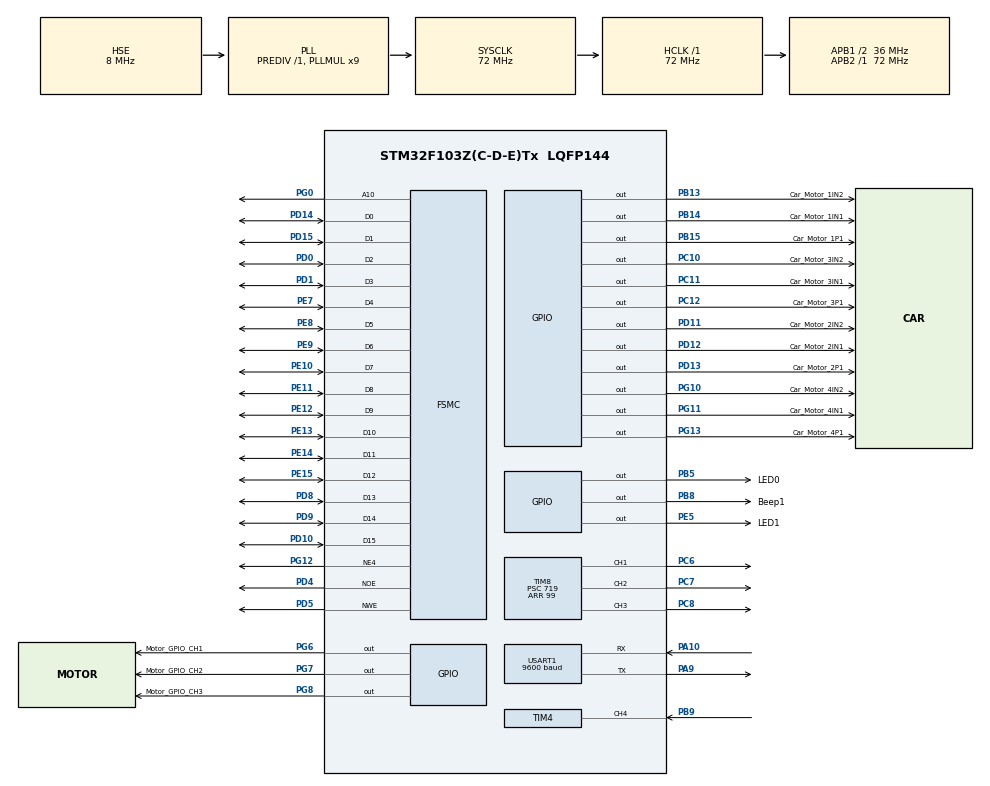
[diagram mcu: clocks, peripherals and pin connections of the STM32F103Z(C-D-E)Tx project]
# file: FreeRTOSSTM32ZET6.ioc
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Dma.Request0=USART1_RX
Dma.Request1=USART1_TX
Dma.USART1_RX.0.Direction=DMA_PERIPH_TO_MEMORY
Dma.USART1_RX.0.Instance=DMA1_Channel5
Dma.USART1_RX.0.MemDataAlignment=DMA_MDATAALIGN_BYTE
Dma.USART1_RX.0.MemInc=DMA_MINC_ENABLE
Dma.USART1_RX.0.Mode=DMA_CIRCULAR
Dma.USART1_RX.0.PeriphDataAlignment=DMA_PDATAALIGN_BYTE
Dma.USART1_RX.0.PeriphInc=DMA_PINC_DISABLE
Dma.USART1_RX.0.Priority=DMA_PRIORITY_LOW
Dma.USART1_TX.1.Direction=DMA_MEMORY_TO_PERIPH
Dma.USART1_TX.1.Instance=DMA1_Channel4
Dma.USART1_TX.1.MemDataAlignment=DMA_MDATAALIGN_BYTE
Dma.USART1_TX.1.MemInc=DMA_MINC_ENABLE
Dma.USART1_TX.1.Mode=DMA_NORMAL
Dma.USART1_TX.1.PeriphDataAlignment=DMA_PDATAALIGN_BYTE
Dma.USART1_TX.1.PeriphInc=DMA_PINC_DISABLE
Dma.USART1_TX.1.Priority=DMA_PRIORITY_LOW
FREERTOS.BinarySemaphores01=uart1_printf_gsem,Dynamic,NULL,Available;uart1_rxok_gsem,Dynamic,NULL,Available;LCD_refresh_gsem,Dynamic,NULL,Available;uart1_data_handle_gsem,Dynamic,NULL,Available
FREERTOS.Tasks01=defauleTask,24,128,StartdefauleTask,As weak,NULL,Dynamic,NULL,NULL;UART1_recv_Task,16,128,StartUART1_recv_TaskFunction,As external,&sys_use_data,Dynamic,NULL,NULL;LCDDisplayTask,8,128,StartLCDDisplayTaskFunction,As external,&sys_use_data,Dynamic,NULL,NULL;LEDProcessedTas,16,128,StartLEDProcessedTaskFunction,As external,&sys_use_data,Dynamic,NULL,NULL;LEDWorkTask,8,128,StartLEDWorkTaskFunction,As external,&sys_use_data,Dynamic,NULL,NULL;TimeSetTask,8,128,StartTimeSetTaskFunction,As external,&sys_use_data,Dynamic,NULL,NULL;BeepWorkTask,8,128,StartBeepWorkTaskFunction,As external,&sys_use_data,Dynamic,NULL,NULL;RobotmainContro,8,128,StartRobotmainControlTask,As external,&sys_use_data,Dynamic,NULL,NULL
FREERTOS.configTOTAL_HEAP_SIZE=10240
FSMC.ExtendedMode1=FSMC_EXTENDED_MODE_ENABLE
Mcu.Family=STM32F1
Mcu.Name=STM32F103Z(C-D-E)Tx
Mcu.Package=LQFP144
NVIC.DMA1_Channel4_IRQn=true\:5\:0\:false\:false\:true\:true\:false\:true\:true
NVIC.DMA1_Channel5_IRQn=true\:5\:0\:false\:false\:true\:true\:false\:true\:true
NVIC.PriorityGroup=NVIC_PRIORITYGROUP_4
NVIC.TIM4_IRQn=true\:5\:0\:false\:false\:true\:true\:true\:true\:true
NVIC.TIM6_IRQn=true\:15\:0\:false\:false\:true\:false\:false\:true\:true
NVIC.TIM8_CC_IRQn=true\:5\:0\:false\:false\:true\:true\:true\:true\:true
NVIC.TimeBase=TIM6_IRQn
NVIC.TimeBaseIP=TIM6
NVIC.USART1_IRQn=true\:5\:0\:false\:false\:true\:true\:true\:true\:true
OSC_IN.Mode=HSE-External-Oscillator
OSC_IN.Signal=RCC_OSC_IN
OSC_OUT.Mode=HSE-External-Oscillator
OSC_OUT.Signal=RCC_OSC_OUT
PA10.Mode=Asynchronous
PA10.Signal=USART1_RX
PA13.Mode=Serial_Wire
PA13.Signal=SYS_JTMS-SWDIO
PA14.Mode=Serial_Wire
PA14.Signal=SYS_JTCK-SWCLK
PA9.Mode=Asynchronous
PA9.Signal=USART1_TX
PB13.GPIO_Label=Car_Motor_1IN2
PB13.GPIO_ModeDefaultOutputPP=GPIO_MODE_OUTPUT_PP
PB13.GPIO_PuPd=GPIO_NOPULL
PB13.GPIO_Speed=GPIO_SPEED_FREQ_HIGH
PB13.PinState=GPIO_PIN_SET
PB13.Signal=GPIO_Output
PB14.GPIO_Label=Car_Motor_1IN1
PB14.GPIO_ModeDefaultOutputPP=GPIO_MODE_OUTPUT_PP
PB14.GPIO_PuPd=GPIO_NOPULL
PB14.GPIO_Speed=GPIO_SPEED_FREQ_HIGH
PB14.PinState=GPIO_PIN_SET
PB14.Signal=GPIO_Output
PB15.GPIO_Label=Car_Motor_1P1
PB15.GPIO_ModeDefaultOutputPP=GPIO_MODE_OUTPUT_PP
PB15.GPIO_PuPd=GPIO_NOPULL
PB15.GPIO_Speed=GPIO_SPEED_FREQ_HIGH
PB15.PinState=GPIO_PIN_SET
PB15.Signal=GPIO_Output
PB5.GPIO_Label=LED0
PB5.GPIO_PuPd=GPIO_PULLUP
PB5.GPIO_Speed=GPIO_SPEED_FREQ_HIGH
PB5.PinState=GPIO_PIN_SET
PB5.Signal=GPIO_Output
PB8.GPIO_Label=Beep1
PB8.Signal=GPIO_Output
PB9.Signal=S_TIM4_CH4
PC10.GPIO_Label=Car_Motor_3IN2
PC10.GPIO_ModeDefaultOutputPP=GPIO_MODE_OUTPUT_PP
PC10.GPIO_PuPd=GPIO_NOPULL
PC10.GPIO_Speed=GPIO_SPEED_FREQ_HIGH
PC10.PinState=GPIO_PIN_SET
PC10.Signal=GPIO_Output
PC11.GPIO_Label=Car_Motor_3IN1
PC11.GPIO_ModeDefaultOutputPP=GPIO_MODE_OUTPUT_PP
PC11.GPIO_PuPd=GPIO_NOPULL
PC11.GPIO_Speed=GPIO_SPEED_FREQ_HIGH
PC11.PinState=GPIO_PIN_SET
PC11.Signal=GPIO_Output
PC12.GPIO_Label=Car_Motor_3P1
PC12.GPIO_ModeDefaultOutputPP=GPIO_MODE_OUTPUT_PP
PC12.GPIO_PuPd=GPIO_NOPULL
PC12.GPIO_Speed=GPIO_SPEED_FREQ_HIGH
PC12.PinState=GPIO_PIN_SET
PC12.Signal=GPIO_Output
PC14-OSC32_IN.Mode=LSE-External-Oscillator
PC14-OSC32_IN.Signal=RCC_OSC32_IN
PC15-OSC32_OUT.Mode=LSE-External-Oscillator
PC15-OSC32_OUT.Signal=RCC_OSC32_OUT
PC6.Signal=S_TIM8_CH1
PC7.Signal=S_TIM8_CH2
PC8.Signal=S_TIM8_CH3
PD0.Signal=FSMC_D2_DA2
PD1.Signal=FSMC_D3_DA3
PD10.Signal=FSMC_D15_DA15
PD11.GPIO_Label=Car_Motor_2IN2
PD11.GPIO_ModeDefaultOutputPP=GPIO_MODE_OUTPUT_PP
PD11.GPIO_PuPd=GPIO_NOPULL
PD11.GPIO_Speed=GPIO_SPEED_FREQ_HIGH
PD11.PinState=GPIO_PIN_SET
PD11.Signal=GPIO_Output
PD12.GPIO_Label=Car_Motor_2IN1
PD12.GPIO_ModeDefaultOutputPP=GPIO_MODE_OUTPUT_PP
PD12.GPIO_PuPd=GPIO_NOPULL
PD12.GPIO_Speed=GPIO_SPEED_FREQ_HIGH
PD12.PinState=GPIO_PIN_SET
PD12.Signal=GPIO_Output
PD13.GPIO_Label=Car_Motor_2P1
PD13.GPIO_ModeDefaultOutputPP=GPIO_MODE_OUTPUT_PP
PD13.GPIO_PuPd=GPIO_NOPULL
PD13.GPIO_Speed=GPIO_SPEED_FREQ_HIGH
PD13.PinState=GPIO_PIN_SET
PD13.Signal=GPIO_Output
PD14.Signal=FSMC_D0_DA0
PD15.Signal=FSMC_D1_DA1
PD4.Signal=FSMC_NOE
PD5.Signal=FSMC_NWE
PD8.Signal=FSMC_D13_DA13
PD9.Signal=FSMC_D14_DA14
PE10.Signal=FSMC_D7_DA7
PE11.Signal=FSMC_D8_DA8
PE12.Signal=FSMC_D9_DA9
PE13.Signal=FSMC_D10_DA10
PE14.Signal=FSMC_D11_DA11
PE15.Signal=FSMC_D12_DA12
PE5.GPIO_Label=LED1
PE5.GPIO_PuPd=GPIO_PULLUP
PE5.GPIO_Speed=GPIO_SPEED_FREQ_HIGH
PE5.PinState=GPIO_PIN_SET
PE5.Signal=GPIO_Output
PE7.Signal=FSMC_D4_DA4
PE8.Signal=FSMC_D5_DA5
PE9.Signal=FSMC_D6_DA6
PG0.Signal=FSMC_A10
PG10.GPIO_Label=Car_Motor_4IN2
PG10.GPIO_ModeDefaultOutputPP=GPIO_MODE_OUTPUT_PP
PG10.GPIO_PuPd=GPIO_NOPULL
PG10.GPIO_Speed=GPIO_SPEED_FREQ_HIGH
PG10.PinState=GPIO_PIN_SET
PG10.Signal=GPIO_Output
PG11.GPIO_Label=Car_Motor_4IN1
PG11.GPIO_ModeDefaultOutputPP=GPIO_MODE_OUTPUT_PP
PG11.GPIO_PuPd=GPIO_NOPULL
PG11.GPIO_Speed=GPIO_SPEED_FREQ_HIGH
PG11.PinState=GPIO_PIN_SET
PG11.Signal=GPIO_Output
PG12.Mode=NorPsramChipSelect4_1
PG12.Signal=FSMC_NE4
PG13.GPIO_Label=Car_Motor_4P1
PG13.GPIO_ModeDefaultOutputPP=GPIO_MODE_OUTPUT_PP
PG13.GPIO_PuPd=GPIO_NOPULL
PG13.GPIO_Speed=GPIO_SPEED_FREQ_HIGH
PG13.PinState=GPIO_PIN_SET
PG13.Signal=GPIO_Output
PG6.GPIO_Label=Motor_GPIO_CH1
PG6.GPIO_ModeDefaultOutputPP=GPIO_MODE_OUTPUT_PP
PG6.GPIO_PuPd=GPIO_NOPULL
PG6.GPIO_Speed=GPIO_SPEED_FREQ_HIGH
PG6.PinState=GPIO_PIN_SET
PG6.Signal=GPIO_Output
PG7.GPIO_Label=Motor_GPIO_CH2
PG7.GPIO_PuPd=GPIO_NOPULL
PG7.GPIO_Speed=GPIO_SPEED_FREQ_HIGH
PG7.PinState=GPIO_PIN_SET
PG7.Signal=GPIO_Output
PG8.GPIO_Label=Motor_GPIO_CH3
PG8.GPIO_PuPd=GPIO_NOPULL
PG8.GPIO_Speed=GPIO_SPEED_FREQ_HIGH
PG8.PinState=GPIO_PIN_SET
PG8.Signal=GPIO_Output
ProjectManager.HeapSize=0x200
ProjectManager.StackSize=0x400
ProjectManager.TargetToolchain=MDK-ARM V5.32
RCC.AHBFreq_Value=72000000
RCC.APB1CLKDivider=RCC_HCLK_DIV2
RCC.APB1Freq_Value=36000000
RCC.APB1TimFreq_Value=72000000
RCC.APB2Freq_Value=72000000
RCC.APB2TimFreq_Value=72000000
RCC.HCLKFreq_Value=72000000
RCC.PLLMUL=RCC_PLL_MUL9
RCC.PLLSourceVirtual=RCC_PLLSOURCE_HSE
RCC.SYSCLKFreq_VALUE=72000000
RCC.SYSCLKSource=RCC_SYSCLKSOURCE_PLLCLK
RCC.USBFreq_Value=72000000
SH.FSMC_A10.0=FSMC_A10,A10_1
SH.FSMC_D0_DA0.0=FSMC_D0,16b-d1
SH.FSMC_D10_DA10.0=FSMC_D10,16b-d1
SH.FSMC_D11_DA11.0=FSMC_D11,16b-d1
SH.FSMC_D12_DA12.0=FSMC_D12,16b-d1
SH.FSMC_D13_DA13.0=FSMC_D13,16b-d1
SH.FSMC_D14_DA14.0=FSMC_D14,16b-d1
SH.FSMC_D15_DA15.0=FSMC_D15,16b-d1
SH.FSMC_D1_DA1.0=FSMC_D1,16b-d1
SH.FSMC_D2_DA2.0=FSMC_D2,16b-d1
SH.FSMC_D3_DA3.0=FSMC_D3,16b-d1
SH.FSMC_D4_DA4.0=FSMC_D4,16b-d1
SH.FSMC_D5_DA5.0=FSMC_D5,16b-d1
SH.FSMC_D6_DA6.0=FSMC_D6,16b-d1
SH.FSMC_D7_DA7.0=FSMC_D7,16b-d1
SH.FSMC_D8_DA8.0=FSMC_D8,16b-d1
SH.FSMC_D9_DA9.0=FSMC_D9,16b-d1
SH.FSMC_NOE.0=FSMC_NOE,Lcd1
SH.FSMC_NWE.0=FSMC_NWE,Lcd1
SH.S_TIM4_CH4.0=TIM4_CH4,Input_Capture4_from_TI4
SH.S_TIM8_CH1.0=TIM8_CH1,PWM Generation1 CH1
SH.S_TIM8_CH2.0=TIM8_CH2,PWM Generation2 CH2
SH.S_TIM8_CH3.0=TIM8_CH3,PWM Generation3 CH3
TIM4.Channel-Input_Capture4_from_TI4=TIM_CHANNEL_4
TIM4.Period=65535
TIM4.Prescaler=72-1
TIM8.Channel-PWM\ Generation1\ CH1=TIM_CHANNEL_1
TIM8.Channel-PWM\ Generation2\ CH2=TIM_CHANNEL_2
TIM8.Channel-PWM\ Generation3\ CH3=TIM_CHANNEL_3
TIM8.Period=99
TIM8.Prescaler=719
USART1.BaudRate=9600
USART1.VirtualMode=VM_ASYNC
VP_FREERTOS_VS_CMSIS_V2.Mode=CMSIS_V2
VP_SYS_VS_tim6.Mode=TIM6
VP_TIM8_VS_ClockSourceINT.Mode=Internal
board=custom

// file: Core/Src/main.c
/* USER CODE BEGIN Header */
/**
  ******************************************************************************
  * @file           : main.c
  * @brief          : Main program body
  ******************************************************************************
  * @attention
  *
  * Copyright (c) 2025 STMicroelectronics.
  * All rights reserved.
  *
  * This software is licensed under terms that can be found in the LICENSE file
  * in the root directory of this software component.
  * If no LICENSE file comes with this software, it is provided AS-IS.
  *
  ******************************************************************************
  */
/* USER CODE END Header */
#include "main.h"
#include "cmsis_os.h"
#include "dma.h"
#include "tim.h"
#include "usart.h"
#include "gpio.h"
#include "fsmc.h"

/* USER CODE BEGIN Includes */
#include "mytask.h"
/* USER CODE END Includes */

void SystemClock_Config(void);
void MX_FREERTOS_Init(void);

int main(void)
{

  /* MCU Configuration--------------------------------------------------------*/

  /* Reset of all peripherals, Initializes the Flash interface and the Systick. */
  HAL_Init();

  /* Configure the system clock */
  SystemClock_Config();

  /* Initialize all configured peripherals */
  MX_GPIO_Init();
  MX_DMA_Init();
  MX_USART1_UART_Init();
  MX_FSMC_Init();
  MX_TIM4_Init();
  MX_TIM8_Init();

  /* Init scheduler */
  osKernelInitialize();

  /* Call init function for freertos objects (in cmsis_os2.c) */
  MX_FREERTOS_Init();

  /* Start scheduler */
  osKernelStart();

  /* We should never get here as control is now taken by the scheduler */

  /* Infinite loop */
  while (1)
  {

  }
}

void SystemClock_Config(void)
{
  RCC_OscInitTypeDef RCC_OscInitStruct = {0};
  RCC_ClkInitTypeDef RCC_ClkInitStruct = {0};

  /** Initializes the RCC Oscillators according to the specified parameters
  * in the RCC_OscInitTypeDef structure.
  */
  RCC_OscInitStruct.OscillatorType = RCC_OSCILLATORTYPE_HSE;
  RCC_OscInitStruct.HSEState = RCC_HSE_ON;
  RCC_OscInitStruct.HSEPredivValue = RCC_HSE_PREDIV_DIV1;
  RCC_OscInitStruct.HSIState = RCC_HSI_ON;
  RCC_OscInitStruct.PLL.PLLState = RCC_PLL_ON;
  RCC_OscInitStruct.PLL.PLLSource = RCC_PLLSOURCE_HSE;
  RCC_OscInitStruct.PLL.PLLMUL = RCC_PLL_MUL9;
  if (HAL_RCC_OscConfig(&RCC_OscInitStruct) != HAL_OK)
  {
    Error_Handler();
  }

  /** Initializes the CPU, AHB and APB buses clocks
  */
  RCC_ClkInitStruct.ClockType = RCC_CLOCKTYPE_HCLK|RCC_CLOCKTYPE_SYSCLK
                              |RCC_CLOCKTYPE_PCLK1|RCC_CLOCKTYPE_PCLK2;
  RCC_ClkInitStruct.SYSCLKSource = RCC_SYSCLKSOURCE_PLLCLK;
  RCC_ClkInitStruct.AHBCLKDivider = RCC_SYSCLK_DIV1;
  RCC_ClkInitStruct.APB1CLKDivider = RCC_HCLK_DIV2;
  RCC_ClkInitStruct.APB2CLKDivider = RCC_HCLK_DIV1;

  if (HAL_RCC_ClockConfig(&RCC_ClkInitStruct, FLASH_LATENCY_2) != HAL_OK)
  {
    Error_Handler();
  }
}

 __weak void HAL_TIM_PeriodElapsedCallback(TIM_HandleTypeDef *htim)
{
  if (htim->Instance == TIM6) {
    HAL_IncTick();
  }
}

void Error_Handler(void)
{
  __disable_irq();
  while (1)
  {
  }
}

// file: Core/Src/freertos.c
/* USER CODE BEGIN Header */
/**
 ******************************************************************************
 * File Name          : freertos.c
 * Description        : Code for freertos applications
 ******************************************************************************
 * @attention
 *
 * Copyright (c) 2025 STMicroelectronics.
 * All rights reserved.
 *
 * This software is licensed under terms that can be found in the LICENSE file
 * in the root directory of this software component.
 * If no LICENSE file comes with this software, it is provided AS-IS.
 *
 ******************************************************************************
 */
/* USER CODE END Header */

#include "FreeRTOS.h"
#include "task.h"
#include "main.h"
#include "cmsis_os.h"

/* USER CODE BEGIN Includes */
#include "mytask.h"
/* USER CODE END Includes */

/* Definitions for defauleTask */
osThreadId_t defauleTaskHandle;
const osThreadAttr_t defauleTask_attributes = {
  .name = "defauleTask",
  .stack_size = 128 * 4,
  .priority = (osPriority_t) osPriorityNormal,
};
/* Definitions for UART1_recv_Task */
osThreadId_t UART1_recv_TaskHandle;
const osThreadAttr_t UART1_recv_Task_attributes = {
  .name = "UART1_recv_Task",
  .stack_size = 128 * 4,
  .priority = (osPriority_t) osPriorityBelowNormal,
};
/* Definitions for LCDDisplayTask */
osThreadId_t LCDDisplayTaskHandle;
const osThreadAttr_t LCDDisplayTask_attributes = {
  .name = "LCDDisplayTask",
  .stack_size = 128 * 4,
  .priority = (osPriority_t) osPriorityLow,
};
/* Definitions for LEDProcessedTas */
osThreadId_t LEDProcessedTasHandle;
const osThreadAttr_t LEDProcessedTas_attributes = {
  .name = "LEDProcessedTas",
  .stack_size = 128 * 4,
  .priority = (osPriority_t) osPriorityBelowNormal,
};
/* Definitions for LEDWorkTask */
osThreadId_t LEDWorkTaskHandle;
const osThreadAttr_t LEDWorkTask_attributes = {
  .name = "LEDWorkTask",
  .stack_size = 128 * 4,
  .priority = (osPriority_t) osPriorityLow,
};
/* Definitions for TimeSetTask */
osThreadId_t TimeSetTaskHandle;
const osThreadAttr_t TimeSetTask_attributes = {
  .name = "TimeSetTask",
  .stack_size = 128 * 4,
  .priority = (osPriority_t) osPriorityLow,
};
/* Definitions for BeepWorkTask */
osThreadId_t BeepWorkTaskHandle;
const osThreadAttr_t BeepWorkTask_attributes = {
  .name = "BeepWorkTask",
  .stack_size = 128 * 4,
  .priority = (osPriority_t) osPriorityLow,
};
/* Definitions for RobotmainContro */
osThreadId_t RobotmainControHandle;
const osThreadAttr_t RobotmainContro_attributes = {
  .name = "RobotmainContro",
  .stack_size = 128 * 4,
  .priority = (osPriority_t) osPriorityLow,
};
/* Definitions for uart1_printf_gsem */
osSemaphoreId_t uart1_printf_gsemHandle;
const osSemaphoreAttr_t uart1_printf_gsem_attributes = {
  .name = "uart1_printf_gsem"
};
/* Definitions for uart1_rxok_gsem */
osSemaphoreId_t uart1_rxok_gsemHandle;
const osSemaphoreAttr_t uart1_rxok_gsem_attributes = {
  .name = "uart1_rxok_gsem"
};
/* Definitions for LCD_refresh_gsem */
osSemaphoreId_t LCD_refresh_gsemHandle;
const osSemaphoreAttr_t LCD_refresh_gsem_attributes = {
  .name = "LCD_refresh_gsem"
};
/* Definitions for uart1_data_handle_gsem */
osSemaphoreId_t uart1_data_handle_gsemHandle;
const osSemaphoreAttr_t uart1_data_handle_gsem_attributes = {
  .name = "uart1_data_handle_gsem"
};

void StartdefauleTask(void *argument);
extern void StartUART1_recv_TaskFunction(void *argument);
extern void StartLCDDisplayTaskFunction(void *argument);
extern void StartLEDProcessedTaskFunction(void *argument);
extern void StartLEDWorkTaskFunction(void *argument);
extern void StartTimeSetTaskFunction(void *argument);
extern void StartBeepWorkTaskFunction(void *argument);
extern void StartRobotmainControlTask(void *argument);

void MX_FREERTOS_Init(void); /* (MISRA C 2004 rule 8.1) */

void MX_FREERTOS_Init(void) {
  /* USER CODE BEGIN Init */
    //完成参数初始化（这里建议使用自定义函数完成后将其放入这个位置）
    SYS_USE_DATA sys_use_data;
  /* USER CODE END Init */

  /* Create the semaphores(s) */
  /* creation of uart1_printf_gsem */
  uart1_printf_gsemHandle = osSemaphoreNew(1, 1, &uart1_printf_gsem_attributes);

  /* creation of uart1_rxok_gsem */
  uart1_rxok_gsemHandle = osSemaphoreNew(1, 1, &uart1_rxok_gsem_attributes);

  /* creation of LCD_refresh_gsem */
  LCD_refresh_gsemHandle = osSemaphoreNew(1, 1, &LCD_refresh_gsem_attributes);

  /* creation of uart1_data_handle_gsem */
  uart1_data_handle_gsemHandle = osSemaphoreNew(1, 1, &uart1_data_handle_gsem_attributes);

  /* Create the thread(s) */
  /* creation of defauleTask */
  defauleTaskHandle = osThreadNew(StartdefauleTask, NULL, &defauleTask_attributes);

  /* creation of UART1_recv_Task */
  UART1_recv_TaskHandle = osThreadNew(StartUART1_recv_TaskFunction, (void*) &sys_use_data, &UART1_recv_Task_attributes);

  /* creation of LCDDisplayTask */
  LCDDisplayTaskHandle = osThreadNew(StartLCDDisplayTaskFunction, (void*) &sys_use_data, &LCDDisplayTask_attributes);

  /* creation of LEDProcessedTas */
  LEDProcessedTasHandle = osThreadNew(StartLEDProcessedTaskFunction, (void*) &sys_use_data, &LEDProcessedTas_attributes);

  /* creation of LEDWorkTask */
  LEDWorkTaskHandle = osThreadNew(StartLEDWorkTaskFunction, (void*) &sys_use_data, &LEDWorkTask_attributes);

  /* creation of TimeSetTask */
  TimeSetTaskHandle = osThreadNew(StartTimeSetTaskFunction, (void*) &sys_use_data, &TimeSetTask_attributes);

  /* creation of BeepWorkTask */
  BeepWorkTaskHandle = osThreadNew(StartBeepWorkTaskFunction, (void*) &sys_use_data, &BeepWorkTask_attributes);

  /* creation of RobotmainContro */
  RobotmainControHandle = osThreadNew(StartRobotmainControlTask, (void*) &sys_use_data, &RobotmainContro_attributes);

}

__weak void StartdefauleTask(void *argument)
{
    for (;;) {
        osDelay(1);
    }
}
